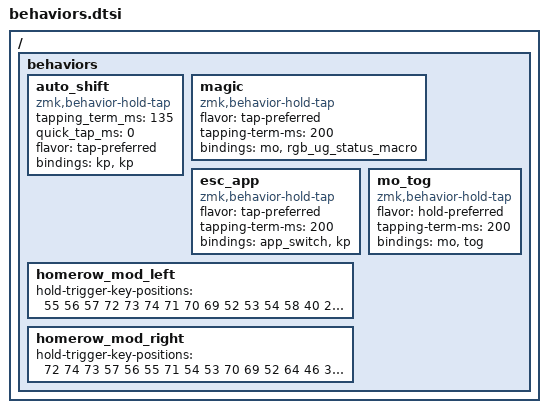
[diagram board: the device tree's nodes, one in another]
#define LAYER_TAP_DANCE(name, layer) \
    td_##name: td_##name { \
        label = #name "_tap_dance"; \
        compatible = "zmk,behavior-tap-dance"; \
        #binding-cells = <0>; \
        tapping-term-ms = <200>; \
        bindings = <&mo layer>, <&tog layer>; \
    };

#define SHIFT(normal, shifted) \
    normal ## _ ## shifted: normal ## _ ## shifted { \
        compatible = "zmk,behavior-mod-morph"; \
        #binding-cells = <0>; \
        bindings = <&kp normal>, <&kp shifted>; \
        mods = <(MOD_LSFT|MOD_RSFT)>; \
    };

#define HOMEROW_MOD \
    compatible = "zmk,behavior-hold-tap"; \
    #binding-cells = <2>; \
    tapping-term-ms = <280>; \
    bindings = <&kp>, <&kp>; \
    flavor = "balanced"; \
    quick-tap-ms = <175>; \
    require-prior-idle-ms = <150>; \
    hold-trigger-on-release;

#define AS(keycode) &auto_shift LS(keycode) keycode

#define LT_SYM(kp) &lt layer_sym kp
#define LT_NAV(kp) &lt layer_nav kp
#define LT_NUM(kp) &lt layer_num kp

#define MO_TOG(layer) &mo_tog layer layer
#define MO_TOG_NUM MO_TOG(layer_num)

#define hma(mod) homerow_mod_left mod A
#define hms(mod) homerow_mod_left mod S
#define hmd(mod) homerow_mod_left mod D
#define hmf(mod) homerow_mod_left mod F
#define hmj(mod) homerow_mod_right mod J
#define hmk(mod) homerow_mod_right mod K
#define hml(mod) homerow_mod_right mod L
#define hmsemi(mod) homerow_mod_right mod SEMI

/ {
    behaviors {
        /* LAYER_TAP_DANCE(sym, layer_sym) */

        /* Redefines symbols that may already be shift-paired in case of future mod change */
        SHIFT(AT, HASH)
        SHIFT(DLLR, AMPS)
        SHIFT(BSLH, PIPE)

        SHIFT(MINUS, UNDER)
        SHIFT(PLUS, EQUAL)
        SHIFT(FSLH, STAR)
        SHIFT(CARET, PRCNT)

        SHIFT(GRAVE, TILDE)
        SHIFT(SQT, DQT)
        SHIFT(COMMA, DOT)
        SHIFT(SEMI, COLON)
        SHIFT(QMARK, EXCL)

        SHIFT(LPAR, RPAR)
        SHIFT(LBKT, RBKT)
        SHIFT(LBRC, RBRC)
        SHIFT(LT, GT)

        auto_shift: auto_shift {
            compatible = "zmk,behavior-hold-tap";
            #binding-cells = <2>;
            tapping_term_ms = <135>;
            quick_tap_ms = <0>;
            flavor = "tap-preferred";
            bindings = <&kp>, <&kp>;
        };

        magic: magic {
            compatible = "zmk,behavior-hold-tap";
            #binding-cells = <2>;
            flavor = "tap-preferred";
            tapping-term-ms = <200>;
            bindings = <&mo>, <&rgb_ug_status_macro>;
        };

        esc_app: esc_app {
            compatible = "zmk,behavior-hold-tap";
            #binding-cells = <2>;
            flavor = "tap-preferred";
            tapping-term-ms = <200>;
            bindings = <&app_switch>, <&kp>;
        };

        mo_tog: mo_tog {
            compatible = "zmk,behavior-hold-tap";
            #binding-cells = <2>;
            flavor = "hold-preferred";
            tapping-term-ms = <200>;
            bindings = <&mo>, <&tog>;
        };

        homerow_mod_left: homerow_mod_left {
            HOMEROW_MOD
            hold-trigger-key-positions = <55 56 57 72 73 74 71 70 69 52 53 54 58 40 28 16 17 5 6 18 29 41 59 75 76 60 42 30 7 19 31 43 61 77 78 79 63 62 44 45 33 32 20 21 9 8>;
        };

        homerow_mod_right: homerow_mod_right {
            HOMEROW_MOD
            hold-trigger-key-positions = <72 74 73 57 56 55 71 54 53 70 69 52 64 46 34 22 10 0 1 11 12 23 24 25 36 37 48 49 67 4 14 15 35 47 65 66 68 2 3 13 26 27 38 39 50 51>;
        };
    };
};
